# QN908XC register map
Vendor: nxp.com; File version: 1.0
CPU: CM4 r0p1, little endian, no MPU, no FPU, 0x3 interrupt priority bits, 0x0 interrupts
Registers are 32-bit, read-write, reset 0x0 unless marked. A register's access mark holds for its fields unless they carry their own. Offsets are from the block's base; [hi:lo] are bit positions; {n}, {i} and the like mark numbered series.

## SYSCON
Base 0x40000000
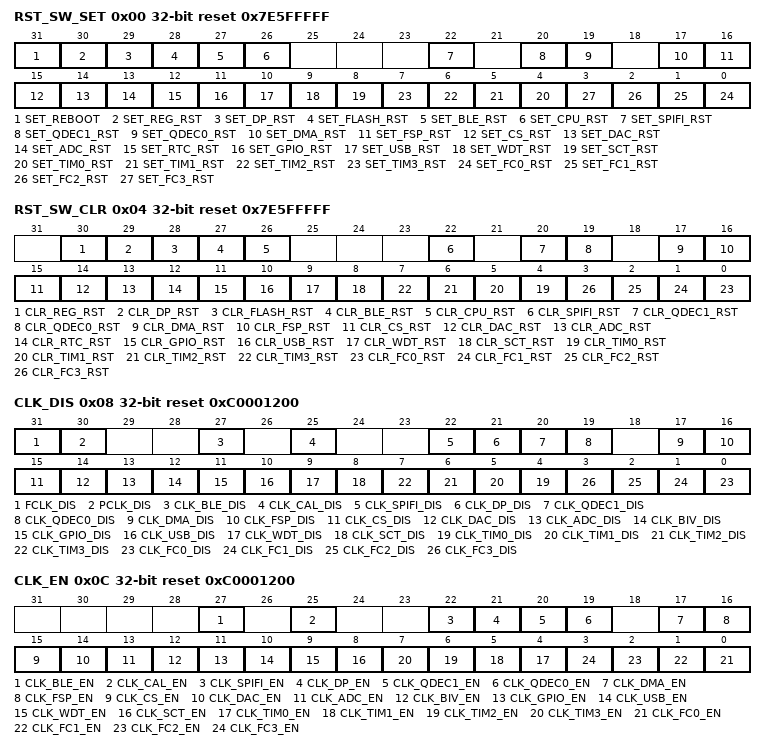
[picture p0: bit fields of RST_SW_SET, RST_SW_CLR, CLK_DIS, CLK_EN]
0x00 RST_SW_SET reset 0x7E5FFFFF — block software reset set register
  [31] SET_REBOOT wo — Write 1 to Reboot entire system
  [30] SET_REG_RST wo — Write 1 to reset retention register
  [29] SET_DP_RST wo — Write 1 to set DataPath reset
  [28] SET_FLASH_RST wo — Write 1 to set flash controller reset
  [27] SET_BLE_RST wo — Write 1 to set BLE reset
  [26] SET_CPU_RST wo — Write 1 to set CPU reset
  [22] SET_SPIFI_RST wo — Write 1 to set SPIFI reset
  [20] SET_QDEC1_RST wo — Write 1 to set QDEC 1 reset
  [19] SET_QDEC0_RST wo — Write 1 to set QDEC 0 reset
  [17] SET_DMA_RST wo — Write 1 to set DMA reset
  [16] SET_FSP_RST wo — Write 1 to set FSP reset
  [15] SET_CS_RST wo — Write 1 to set Cap sensor interface reset
  [14] SET_DAC_RST wo — Write 1 to set DAC interface reset
  [13] SET_ADC_RST wo — Write 1 to set ADC interface reset
  [12] SET_RTC_RST wo — Write 1 to set RTC reset
  [11] SET_GPIO_RST wo — Write 1 to set GPIO reset
  [10] SET_USB_RST wo — Write 1 to set USB reset
  [9] SET_WDT_RST wo — Write 1 to set Watch Dog reset
  [8] SET_SCT_RST wo — Write 1 to set SCT reset
  [n+4] SET_TIM{n}_RST wo (n=0..3) — Write 1 to set CTIMER{n} reset
  [n] SET_FC{n}_RST wo (n=0..3) — Write 1 to set FLEXCOMM{n} reset
0x04 RST_SW_CLR reset 0x7E5FFFFF — block software reset clear register
  [30] CLR_REG_RST write-1-clears — Write 1 to clear retention register reset
  [29] CLR_DP_RST write-1-clears — Write 1 to clear DataPath reset
  [28] CLR_FLASH_RST write-1-clears — Write 1 to clear flash controller reset
  [27] CLR_BLE_RST write-1-clears — Write 1 to clear BLE reset
  [26] CLR_CPU_RST write-1-clears — Write 1 to clear CPU reset
  [22] CLR_SPIFI_RST write-1-clears — Write 1 to clear SPIFI reset
  [20] CLR_QDEC1_RST write-1-clears — Write 1 to clear QDEC 1 reset
  [19] CLR_QDEC0_RST write-1-clears — Write 1 to clear QDEC 0 reset
  [17] CLR_DMA_RST write-1-clears — Write 1 to clear DMA reset
  [16] CLR_FSP_RST write-1-clears — Write 1 to clear FSP reset
  [15] CLR_CS_RST write-1-clears — Write 1 to clear cap sensor interface reset
  [14] CLR_DAC_RST write-1-clears — Write 1 to clear DAC interface reset
  [13] CLR_ADC_RST write-1-clears — Write 1 to clear ADC interface reset
  [12] CLR_RTC_RST write-1-clears — Write 1 to clear RTC reset
  [11] CLR_GPIO_RST write-1-clears — Write 1 to clear GPIO reset
  [10] CLR_USB_RST write-1-clears — Write 1 to clear USB reset
  [9] CLR_WDT_RST write-1-clears — Write 1 to clear Watch Dog reset
  [8] CLR_SCT_RST write-1-clears — Write 1 to clear SCT reset
  [n+4] CLR_TIM{n}_RST write-1-clears (n=0..3) — Write 1 to clear CTIMER{n} reset
  [n] CLR_FC{n}_RST write-1-clears (n=0..3) — Write 1 to clear FLEXCOMM{n} reset
0x08 CLK_DIS reset 0xC0001200 — clock disable register
  [31] FCLK_DIS write-1-clears — Write 1 to disable CPU FCLK;
  [30] PCLK_DIS write-1-clears — Write 1 to disable PCLK of some logic;
  [27] CLK_BLE_DIS write-1-clears — Write 1 to disable BLE clock
  [25] CLK_CAL_DIS write-1-clears — Write 1 to disable Calibration clock;
  [22] CLK_SPIFI_DIS write-1-clears — Write 1 to disable SPIFI clock;
  [21] CLK_DP_DIS write-1-clears — Write 1 to disable Data Path 16/8MHz clock;
  [20] CLK_QDEC1_DIS write-1-clears — Write 1 to disable QDEC1 clock;
  [19] CLK_QDEC0_DIS write-1-clears — Write 1 to disable QDEC0 clock;
  [17] CLK_DMA_DIS write-1-clears — Write 1 to disable DMA clock
  [16] CLK_FSP_DIS write-1-clears — Write 1 to disable FSP clock;
  [15] CLK_CS_DIS write-1-clears — Write 1 to disable Cap sensor clock;
  [14] CLK_DAC_DIS write-1-clears — Write 1 to disable DAC clock;
  [13] CLK_ADC_DIS write-1-clears — Write 1 to disable ADC clock;
  [12] CLK_BIV_DIS write-1-clears — Write 1 to disable BIV APB clock include RTC BiV register.
  [11] CLK_GPIO_DIS write-1-clears — Write 1 to disable GPIO clock
  [10] CLK_USB_DIS write-1-clears — Write 1 to disable USB clock;
  [9] CLK_WDT_DIS write-1-clears — Write 1 to disable Watch Dog clock
  [8] CLK_SCT_DIS write-1-clears — Write 1 to disable SCT clock
  [n+4] CLK_TIM{n}_DIS write-1-clears (n=0..3) — Write 1 to disable CTIMER{n} clock
  [n] CLK_FC{n}_DIS write-1-clears (n=0..3) — Write 1 to disable FLEXCOMM{n} clock
0x0C CLK_EN reset 0xC0001200 — clock enable register
  [27] CLK_BLE_EN wo — Write 1 to enable BLE clock
  [25] CLK_CAL_EN wo — Write 1 to enable Calibration clock;
  [22] CLK_SPIFI_EN wo — Write 1 to enable SPIFI clock;
  [21] CLK_DP_EN wo — Write 1 to enable Data Path 16/8MHz clock;
  [20] CLK_QDEC1_EN wo — Write 1 to enable QDEC1 clock;
  [19] CLK_QDEC0_EN wo — Write 1 to enable QDEC0 clock;
  [17] CLK_DMA_EN wo — Write 1 to enable DMA clock
  [16] CLK_FSP_EN wo — Write 1 to enable FSP clock;
  [15] CLK_CS_EN wo — Write 1 to enable Cap sensor clock;
  [14] CLK_DAC_EN wo — Write 1 to enable DAC clock;
  [13] CLK_ADC_EN wo — Write 1 to enable ADC clock;
  [12] CLK_BIV_EN wo — Write 1 to enable BIV APB clock include RTC BiV register.
  [11] CLK_GPIO_EN wo — Write 1 to enable GPIO clock
  [10] CLK_USB_EN wo — Write 1 to enable USB clock;
  [9] CLK_WDT_EN wo — Write 1 to enable Watch Dog clock
  [8] CLK_SCT_EN wo — Write 1 to enable SCT clock
  [n+4] CLK_TIM{n}_EN wo (n=0..3) — Write 1 to enable CTIMER{n} clock
  [n] CLK_FC{n}_EN wo (n=0..3) — Write 1 to enable FLEXCOMM{n} clock
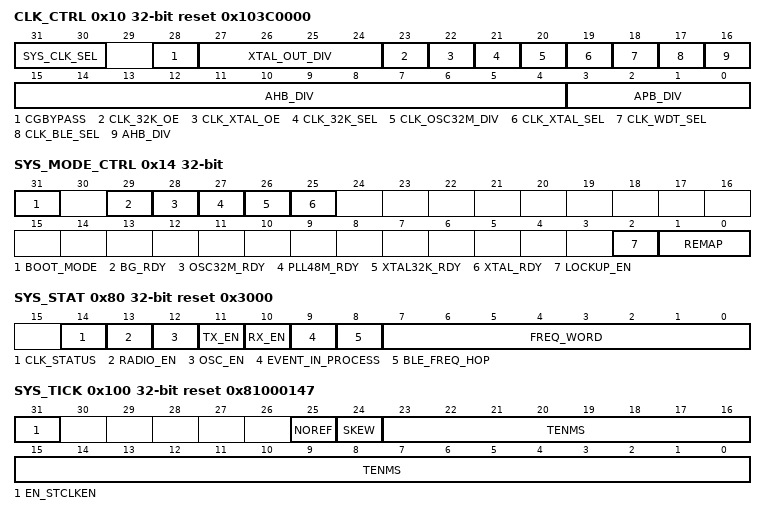
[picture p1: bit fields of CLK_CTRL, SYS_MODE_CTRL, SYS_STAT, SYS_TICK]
0x10 CLK_CTRL reset 0x103C0000 — system clock source and divider register
  [31:30] SYS_CLK_SEL — Select SYS_CLK source
    0=CLK_OSC (32M internal clock); 1=CLK_XTAL (external crystal clock); 2=CLK_32K (32K clock)
  [28] CGBYPASS — If it is 0, it can save CPU power in active mode
  [27:24] XTAL_OUT_DIV — high frequency xtal clock output divider
  [23] CLK_32K_OE — 32K clock output enable
  [22] CLK_XTAL_OE — system clock output enable
  [21] CLK_32K_SEL — 32K clock source selection
    0=XTAL32K (digital 32K clock source is external 32K crystal); 1=RCO32K (digital 32K clock source is internal 32K RCO)
  [20] CLK_OSC32M_DIV — digital OSC clock input selection
    0=BY1 (use original 32M RCO clock); 1=BY2 (divide 32M OSC clock into 16M)
  [19] CLK_XTAL_SEL — Crytal clock selection
    0=XTAL16M (external crystal is 16M); 1=XTAL32M (external crystal is 32M)
  [18] CLK_WDT_SEL — Select Watch Dog clock
    0=CLK_WDT_SEL_32K (watch dog run at 32K); 1=APB (watch dog run at APB clock)
  [17] CLK_BLE_SEL — BLE frequency indicator
    0=CLK_BLE_SEL_8M (BLE run at 8M); 1=CLK_BLE_SEL_16M (BLE run at 16M)
  [16:4] AHB_DIV — AHB_CLK = SYS_CLK / (AHB_DIV+1);Note Before enable BLE clock (CLK_BLE_EN =1) It is mandatory to set AHB_CLK = 32 or 16 or 8 MHz.
  [3:0] APB_DIV — APB_CLK = AHB_CLK/(APB_DIV+1)
0x14 SYS_MODE_CTRL — system mode and address remap register
  [31] BOOT_MODE ro — boot mode pin status
    0=ISP (when BOOT_MODE pin is 0, bootloader enter ISP); 1=NORMAL (when BOOT_MODE pin is 1, bootloader jump to flash without ISP)
  [29] BG_RDY ro — BG ready readout
  [28] OSC32M_RDY ro — 32MHz oscillator ready readout
  [27] PLL48M_RDY ro — 48MHz PLL ready readout
  [26] XTAL32K_RDY ro — 32KHz xtal ready readout
  [25] XTAL_RDY ro — 16/32 MHz xtal ready readout
  [2] LOCKUP_EN — lock up enable
  [1:0] REMAP — software remap system address
    0=ROM (address 0 is mapped to ROM); 1=FLASH (address 0 is mapped to FLASH); 2=RAM (address 0 is mapped to RAM)
0x80 SYS_STAT ro reset 0x3000 — system status register
  [14] CLK_STATUS — BLE status
    0=BLE_IP_ACT (BLE is active); 1=BLE_IP_SLP (BLE is in sleep mode)
  [13] RADIO_EN — BLE radio_en output;
  [12] OSC_EN — BLE osc_en output;
  [11] TX_EN — when 1, system is in TX state
  [10] RX_EN — when 1, system is in RX state
  [9] EVENT_IN_PROCESS — BLE event indicator
    0=BLE_NONE_ENV (BLE is not in event process); 1=BLE_IN_ENV (BLE is in event process)
  [8] BLE_FREQ_HOP — BLE frequency word change flag;
  [7:0] FREQ_WORD — BLE Frequency word;
0x100 SYS_TICK reset 0x81000147 — systick timer control register
  [31] EN_STCLKEN — 1 is enable STCLKEN;
  [25] NOREF — whether an external reference clock is available
    0=AVAILABLE (external reference clock is available); 1=NOT_AVAILABLE (external reference clock is not available)
  [24] SKEW — whether THE TENMS value will generate a precise 10 millisencod time or an approximation
    0=PRECISE (TENMS is considered to be precise); 1=NOT_PRECISE (TENMS is not considered to be precise)
  [23:0] TENMS — system tick timer calibration value
0x104 SRAM_CTRL reset 0x2400 — Exchange memory base address register
  [14:0] EM_BASE_ADDR — Exchange memory base address in system memory. Default value is 9K word.
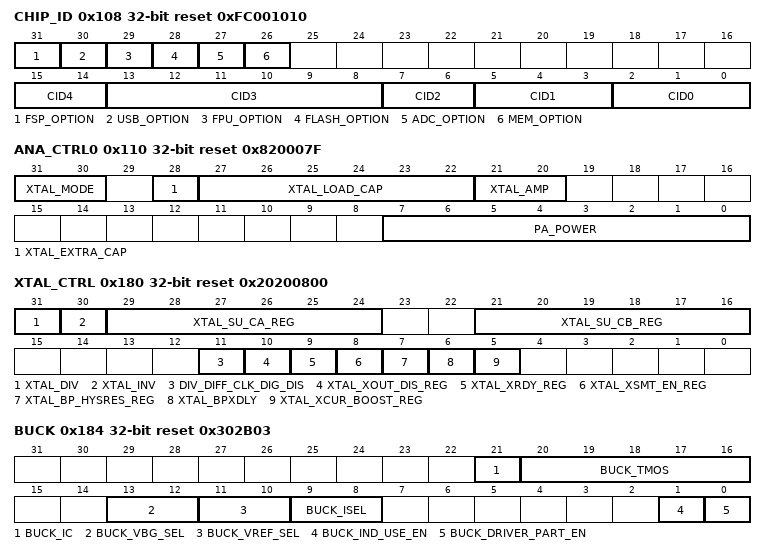
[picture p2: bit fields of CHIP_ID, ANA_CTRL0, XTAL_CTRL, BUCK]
0x108 CHIP_ID ro reset 0xFC001010
  [31] FSP_OPTION — fsp bond indicator
    0=NONE (chip doesnot have FSP); 1=EXIST (chip has FSP)
  [30] USB_OPTION — usb bond indicator
    0=NONE (chip doesnot have USB); 1=EXIST (chip has USB)
  [29] FPU_OPTION — fpu bond indicator
    0=NONE (fpu is not exist); 1=EXIST (fpu is exist)
  [28] FLASH_OPTION — flash bond indicator
    0=FLASH_OPTION_256K (chip flash size is 256K); 1=FLASH_OPTION_512K (chip flash size is 512K)
  [27] ADC_OPTION — adc bond indicator
    0=LOW (adc low resolution); 1=HIGH (adc high resolution)
  [26] MEM_OPTION — memory bond indicator
    0=MEM_OPTION_64K (chip memory size is 64K); 1=MEM_OPTION_128K (chip memory size is 128K)
  [15:14] CID4 — CHIP ID for major revision
    0=A (revision A); 1=B (revision B); 2=C (revision C); 3=D (revision D)
  [13:8] CID3 — CHIP ID for product ID
    0=QN9020; 1=QN9030; 2=QN9080
  [7:6] CID2 — CHIP ID for minor revision
  [5:3] CID1 — CHIP ID for product family
  [2:0] CID0 — CHIP ID for manufacture fab
0x110 ANA_CTRL0 reset 0x820007F — crystal and PA register
  [31:30] XTAL_MODE — Injection mode of the XTAL
    0=XTAL (High frequency crystal oscillator); 1=DIG (Inject digital clock); 2=SINGLE (Inject single-end sine-wave signal); 3=DIFF (inject differential sine-wave signal)
  [28] XTAL_EXTRA_CAP — Add extra 16/32 MHz xtal load cap
  [27:22] XTAL_LOAD_CAP — Register controlled load cap of the XTAL in normal modeLOAD_CAP=5pF+0.35pF*CSEL+5pF*XADD_C
  [21:20] XTAL_AMP — crystal amplitude set register
  [7:0] PA_POWER — PA power control (all of below is minus data)
    16=PA_POWER_20DBM (20dBm); 18=PA_POWER_18DBM (18dBm); 20=PA_POWER_16DBM (16dBm); 25=PA_POWER_14DBM (14dBm); 32=PA_POWER_12DBM (12dBm); 40=PA_POWER_10DBM (10dBm); 50=PA_POWER_8DBM (8dBm); 64=PA_POWER_6DBM (6dBm); 80=PA_POWER_4DBM (4dBm); 101=PA_POWER_2DBM (2dBm); 127=PA_POWER_0DBM (0dBm)
0x180 XTAL_CTRL reset 0x20200800 — crystal control register
  [31] XTAL_DIV — Divide crystal clock when external crystal is 32M this bit should be configured into 1 otherwise 0.
  [30] XTAL_INV — Inverse crystal clock
  [29:24] XTAL_SU_CA_REG — Register controlled load cap of the XTAL_A in speed up modeCA=2pF+0.35pF*SU_CA+5pF*XADD_C
  [21:16] XTAL_SU_CB_REG — Register controlled load cap of the XTAL_B in speed up modeCB=2pF+0.35pF*SU_CB+5pF*XADD_C
  [11] DIV_DIFF_CLK_DIG_DIS — disable differential clock of digital
  [10] XTAL_XOUT_DIS_REG — 1 not to send 16/32 MHz xtal clk out
  [9] XTAL_XRDY_REG — 1 to set xtal ready signal by register
  [8] XTAL_XSMT_EN_REG — 1 to use hysteresis buffer
  [7] XTAL_BP_HYSRES_REG — 1 to bypass the degeneration resistor in order to reduce the hysteresis voltage
  [6] XTAL_BPXDLY — Bypass the power up delay in the XTAL core.
  [5] XTAL_XCUR_BOOST_REG — 1 to increase 16/32 MHz xtal current
0x184 BUCK reset 0x302B03 — buck control register
  [21] BUCK_IC — frequency compensation versus BVDD variation
  [20:16] BUCK_TMOS — buck constant on time control
  [13:12] BUCK_VBG_SEL — buck reference setting
  [11:10] BUCK_VREF_SEL — buck current setting
  [9:8] BUCK_ISEL — buck current bias control
  [1] BUCK_IND_USE_EN — 1 to turn on buck output stage gradually
  [0] BUCK_DRIVER_PART_EN — 1 to short external inductor
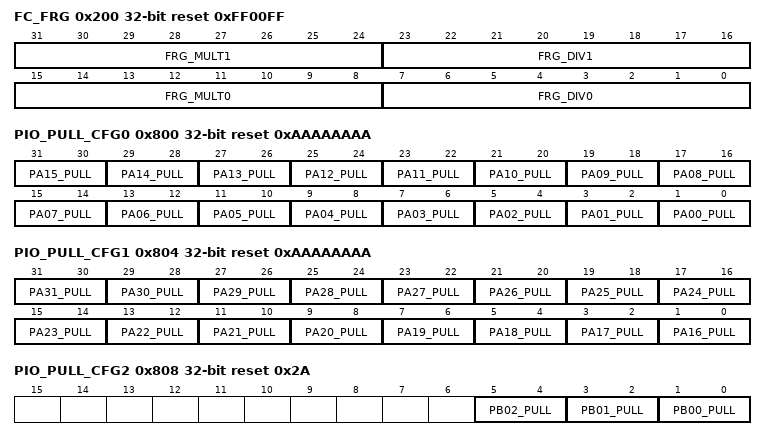
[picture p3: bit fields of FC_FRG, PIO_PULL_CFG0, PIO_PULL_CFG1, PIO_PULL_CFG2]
0x200 FC_FRG reset 0xFF00FF — flexcomm 0 and 1 clock divider register
  [31:24] FRG_MULT1 — flexcomm1 clock generator, Numerator of the fractional divider. MULT is equal to the programmed value
  [23:16] FRG_DIV1 — flexcomm1 clock generator, Denominator of the fractional divider. DIV is equal to the programmed value +1. Always set to 0xFF to use with the fractional baud rate generator.
  [15:8] FRG_MULT0 — flexcomm0 clock generator, Numerator of the fractional divider. MULT is equal to the programmed value
  [7:0] FRG_DIV0 — flexcomm0 clock generator, Denominator of the fractional divider. DIV is equal to the programmed value +1. Always set to 0xFF to use with the fractional baud rate generator.
0x800 PIO_PULL_CFG0 reset 0xAAAAAAAA — pad pull control register 0
  [2n+1:2n] PA{n:02}_PULL (n=0..15) — PA{n:02} pull control register
0x804 PIO_PULL_CFG1 reset 0xAAAAAAAA — pad pull control register 1
  [2n-31:2n-32] PA{n}_PULL (n=16..31) — PA{n} pull control register
0x808 PIO_PULL_CFG2 reset 0x2A — pad pull control register 2
  [5:4] PB02_PULL — PB02 pull control register
  [3:2] PB01_PULL — PB01 pull control register
  [1:0] PB00_PULL — PB00 pull control register
0x80C IO_CAP reset not defined — io status capture register
  [0] PIN_RETENTION wo — Write 1 to capture pad output and output enable and the status will be saved in PIN_SLP_OEN0 PIN_SLP_OEN1 PIN_SLP_OUT0 and PIN_SLP_OUT1.
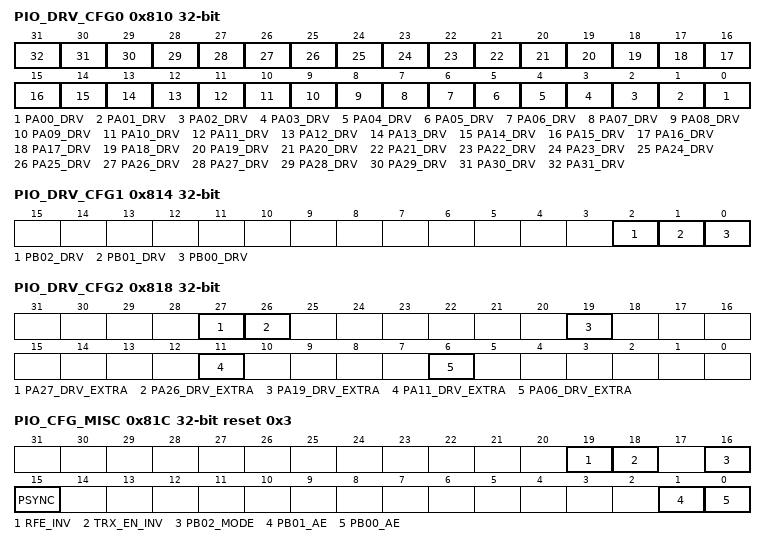
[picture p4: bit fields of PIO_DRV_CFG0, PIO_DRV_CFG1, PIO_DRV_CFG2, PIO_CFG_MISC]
0x810 PIO_DRV_CFG0 — pad drive strength register 0
  [n] PA{n:02}_DRV (n=0..31) — PA{n:02} drive strength register
0x814 PIO_DRV_CFG1 — pad drive strength register 1
  [2] PB02_DRV — PB02 drive strengh register
  [1] PB01_DRV — PB01 drive strengh register
  [0] PB00_DRV — PB00 drive strengh register
0x818 PIO_DRV_CFG2 — pad drive extra register
  [27] PA27_DRV_EXTRA — Write 1 to enable extra driven on PA27
  [26] PA26_DRV_EXTRA — Write 1 to enable extra driven on PA26
  [19] PA19_DRV_EXTRA — Write 1 to enable extra driven on PA19
  [11] PA11_DRV_EXTRA — Write 1 to enable extra driven on PA11
  [6] PA06_DRV_EXTRA — Write 1 to enable extra driven on PA06
0x81C PIO_CFG_MISC reset 0x3 — pin misc control register
  [19] RFE_INV — Inverse RFE polarity
    0=RFE_POL (Inverse RFE polarity)
  [18] TRX_EN_INV — inverse TX_EN & RX_EN pin mux output polarity
    0=TRX_EN_POL (inverse TX_EN & RX_EN pin mux output polarity)
  [16] PB02_MODE — chip mode pin function select
    0=BOOT_MODE (PB02 is used as chip mode input); 1=ANTENNA (PB02 is used as antena output)
  [15] PSYNC — when 1, bypass first stage of synchronization of DMA pin trigger
  [1] PB01_AE — Enable PB01 analog function
  [0] PB00_AE — Enable PB00 analog function
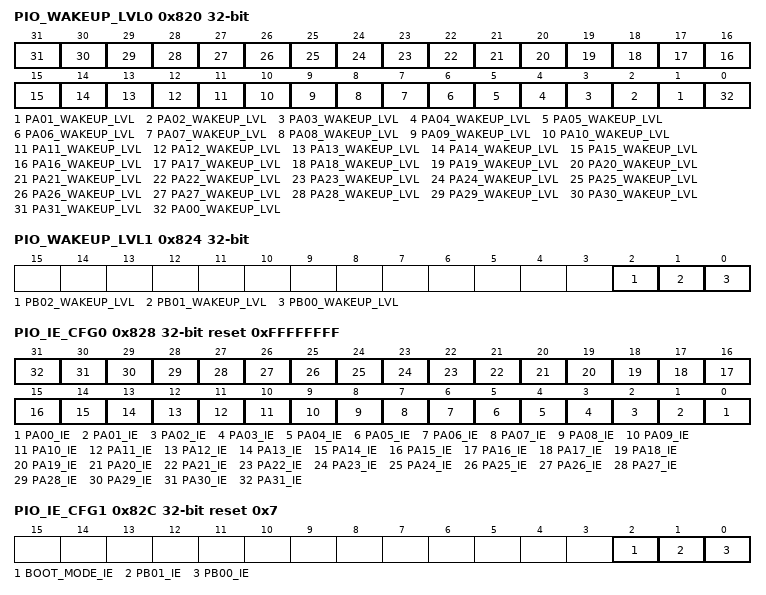
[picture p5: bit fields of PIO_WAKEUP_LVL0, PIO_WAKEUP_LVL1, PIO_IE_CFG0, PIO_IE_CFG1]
0x820 PIO_WAKEUP_LVL0 — pin wakeup polarity register 0
  [n] PA{n:02}_WAKEUP_LVL (n=1..31) — Control the wake up polarity of PA{n:02} in sleep mode.
  [0] PA00_WAKEUP_LVL — Control the wake up polarity of PA00 in sleep mode. 0: high level wakeup, 1: low level wakeup
0x824 PIO_WAKEUP_LVL1 — pin wakeup polarity register 1
  [2] PB02_WAKEUP_LVL — Control the wake up polarity of PB03 in sleep mode.
  [1] PB01_WAKEUP_LVL — Control the wake up polarity of PB02 in sleep mode.
  [0] PB00_WAKEUP_LVL — Control the wake up polarity of PB01 in sleep mode.
0x828 PIO_IE_CFG0 reset 0xFFFFFFFF — pad input enable register 0
  [n] PA{n:02}_IE (n=0..31) — PA{n:02} digital input enable
0x82C PIO_IE_CFG1 reset 0x7 — pad input enable register 1
  [2] BOOT_MODE_IE — PB02 input enable
  [1] PB01_IE — PB01 digital input enable
  [0] PB00_IE — PB00 digital input enable
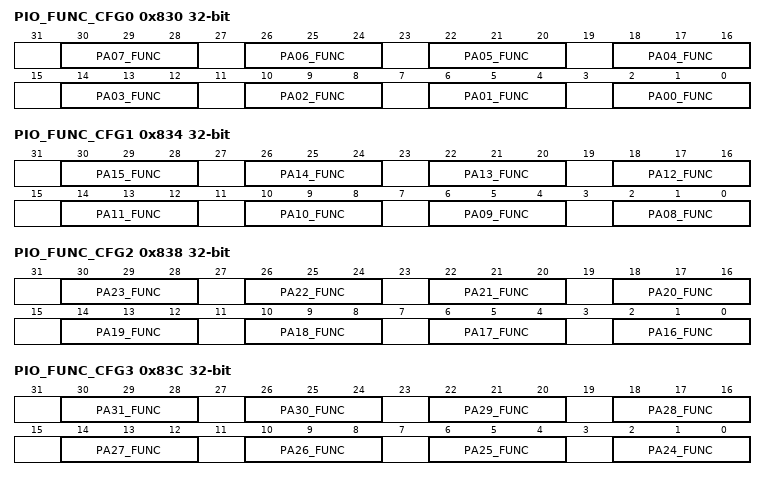
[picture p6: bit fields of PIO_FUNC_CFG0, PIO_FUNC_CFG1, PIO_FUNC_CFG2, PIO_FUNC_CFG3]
0x830 PIO_FUNC_CFG0 — pin mux control register 0
  [4n+2:4n] PA{n:02}_FUNC (n=0..7) — PA{n:02} function control register
0x834 PIO_FUNC_CFG1 — pin mux control register 1
  [4n-30:4n-32] PA{n:02}_FUNC (n=8..15) — PA{n:02} function control register
0x838 PIO_FUNC_CFG2 — pin mux control register 2
  [4n-62:4n-64] PA{n}_FUNC (n=16..23) — PA{n} function control register
0x83C PIO_FUNC_CFG3 — pin mux control register 3
  [4n-94:4n-96] PA{n}_FUNC (n=24..31) — PA{n} function control register
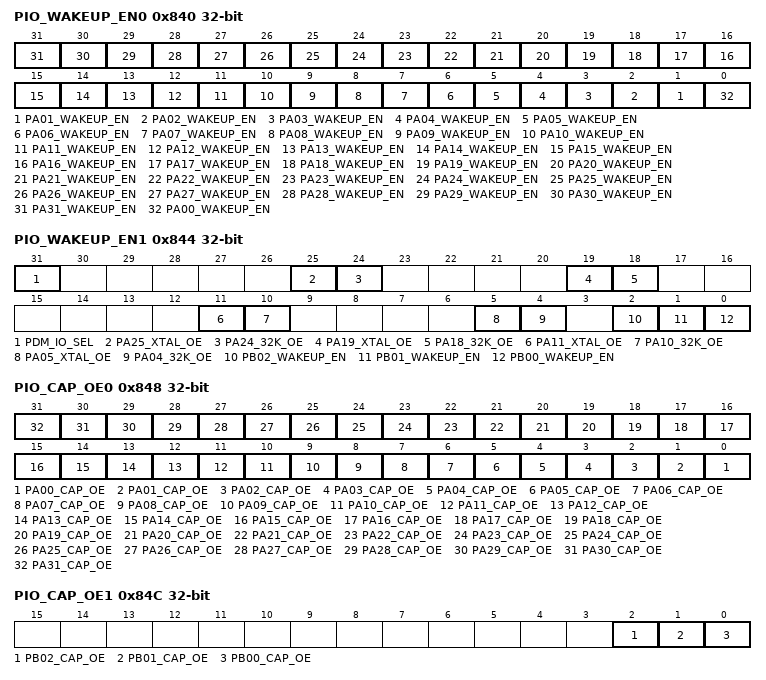
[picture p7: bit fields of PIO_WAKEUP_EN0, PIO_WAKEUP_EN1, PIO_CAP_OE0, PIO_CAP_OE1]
0x840 PIO_WAKEUP_EN0 — pin function selection in power down mode register 0
  [n] PA{n:02}_WAKEUP_EN (n=1..31)
  [0] PA00_WAKEUP_EN — Control GPIOA[31-0] as Wakeup source.
0x844 PIO_WAKEUP_EN1 — pin function selection in power down mode register 1
  [31] PDM_IO_SEL — pin status selection in power down mode
  [25] PA25_XTAL_OE — XTAL clock output enable. When this bit is set to 1 PA25 will output XTAL clock. At this time PIN_CTRL register is not effective to control this IO's function.
  [24] PA24_32K_OE — 32K clock output enable. When this bit is set to 1 PA24 will output 32k clock. At this time PIN_CTRL register is not effective to control this IO's function.
  [19] PA19_XTAL_OE — XTAL clock output enable. When this bit is set to 1 PA19 will output XTAL clock. At this time PIN_CTRL register is not effective to control this IO's function.
  [18] PA18_32K_OE — 32K clock output enable. When this bit is set to 1 PA18 will output 32k clock. At this time PIN_CTRL register is not effective to control this IO's function.
  [11] PA11_XTAL_OE — XTAL clock output enable. When this bit is set to 1 PA11 will output XTAL clock. At this time PIN_CTRL register is not effective to control this IO's function.
  [10] PA10_32K_OE — 32K clock output enable. When this bit is set to 1 PA10 (GPIO10) will output 32k clock. At this time PIN_CTRL register is not effective to control this IO's function.
  [5] PA05_XTAL_OE — XTAL clock output enable. When this bit is set to 1 PA05 will output XTAL clock. At this time PIN_CTRL register is not effective to control this IO's function.
  [4] PA04_32K_OE — 32K clock output enable. When this bit is set to 1 PA04 will output 32k clock. At this time PIN_CTRL register is not effective to control this IO's function.
  [2] PB02_WAKEUP_EN
  [1] PB01_WAKEUP_EN
  [0] PB00_WAKEUP_EN — Control GPIOB as Wakeup source.
0x848 PIO_CAP_OE0 ro — pin output enable status register 0 while captured by writing 1 to IO_CAP
  [n] PA{n:02}_CAP_OE (n=0..31) — PA{n:02} output enable status captured by writing 1 to IO_CAP
0x84C PIO_CAP_OE1 ro — pin output enable status register 1 while captured by writing 1 to IO_CAP
  [2] PB02_CAP_OE — PB02 output enable status captured by writing 1 to IO_CAP
  [1] PB01_CAP_OE — PB01 output enable status captured by writing 1 to IO_CAP
  [0] PB00_CAP_OE — PB00 output enable status captured by writing 1 to IO_CAP
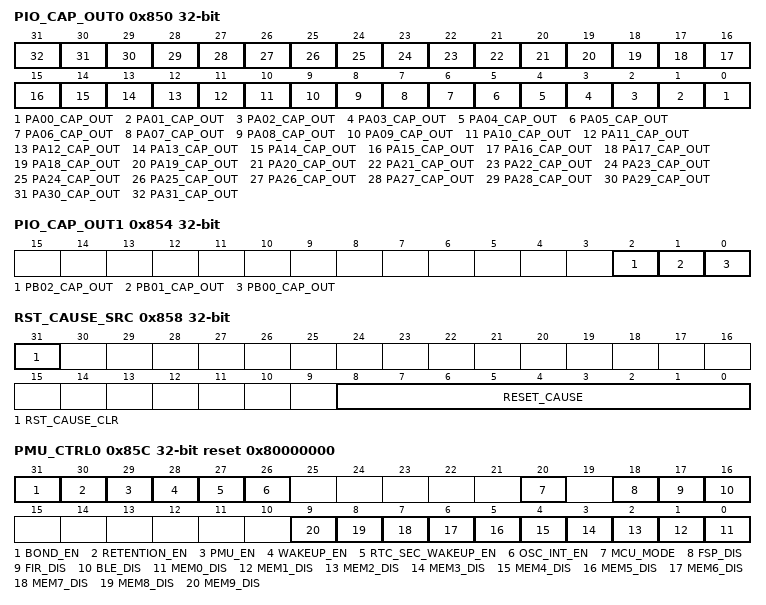
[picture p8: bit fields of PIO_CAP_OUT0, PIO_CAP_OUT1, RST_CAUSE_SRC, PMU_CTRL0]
0x850 PIO_CAP_OUT0 ro — pin output status register 0 while captured by writing 1 to IO_CAP
  [n] PA{n:02}_CAP_OUT (n=0..31) — PA{n:02} output status captured by writing 1 to IO_CAP
0x854 PIO_CAP_OUT1 ro — pin output status register 0 while captured by writing 1 to IO_CAP
  [2] PB02_CAP_OUT — PB02 output status while captured by writing 1 to IO_CAP
  [1] PB01_CAP_OUT — PB01 output status while captured by writing 1 to IO_CAP
  [0] PB00_CAP_OUT — PB00 output status while captured by writing 1 to IO_CAP
0x858 RST_CAUSE_SRC (reset mask 0x1FF) — reset source status register
  [31] RST_CAUSE_CLR wo — Write '1' clear RESET_CAUSE bits;
  [8:0] RESET_CAUSE ro — reset source indicator. xxxxxxxx1b = Power-on Reset; xxxxxxx1xb = Brown-Down Reset; xxxxxx1xxb = External pin Reset; xxxxx1xxxb = Watch Dog Reset; xxxx1xxxxb = Lock Up Reset; xxx1xxxxxb = Reboot Reset; xx1000000b = CPU system Reset requirement; x10000000b = Wake Up reset 10000000b = CPU software Reset;
0x85C PMU_CTRL0 reset 0x80000000 — power management uinit control register 0
  [31] BOND_EN — 1 to enable FSP_BOND_EN bond option
  [30] RETENTION_EN — 1 to enable all CPU registers to be retentioned in sleep mode
  [29] PMU_EN — 1 to enable chip power down mode
  [28] WAKEUP_EN — 1 to enable sleep wake up source
  [27] RTC_SEC_WAKEUP_EN — 1 to enable RTC interrupt as wakeup source
  [26] OSC_INT_EN — 1 to enable OSC_EN as interrupt and wakeup source
  [20] MCU_MODE — power control of BG, V2I, VREG_A, VREG_D
    0=ANA_PWRON (power on BG, V2I, VREG_A, VREG_D); 1=ANA_PWROFF (power off BG, V2I, VREG_A, VREG_D)
  [18] FSP_DIS — power down FSP
  [17] FIR_DIS — power down FIR buffer
  [16] BLE_DIS — power down BLE
  [n] MEM{n}_DIS (n=0..9) — power down sram memory block {n}
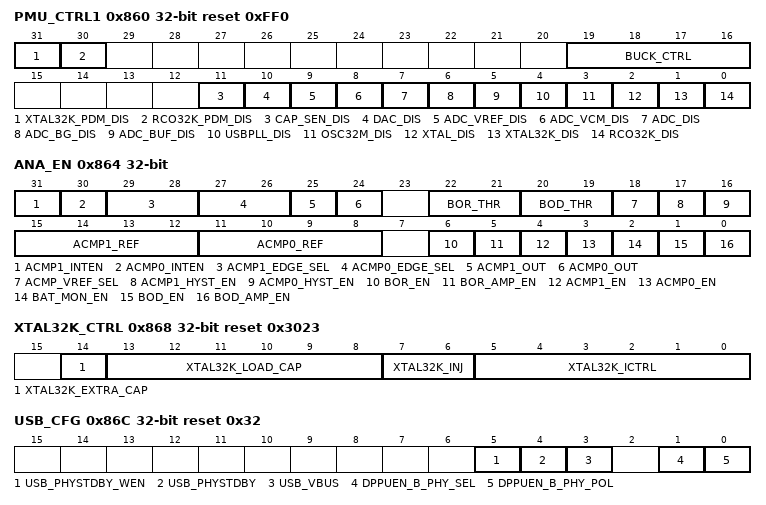
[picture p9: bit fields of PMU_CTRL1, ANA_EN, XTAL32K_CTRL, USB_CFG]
0x860 PMU_CTRL1 reset 0xFF0 — power management uinit control register 1
  [31] XTAL32K_PDM_DIS — In sleep mode this bit ORs with DIS_XTAL32K to control the XTAL32 power
  [30] RCO32K_PDM_DIS — In sleep mode this bit ORs with DIS_RCO_32K to control the RCO 32K power
  [19:16] BUCK_CTRL — BUCK power control, 0x00 to power on, and 0x0F to power down
  [11] CAP_SEN_DIS — 1 to switch off CAP_SEN
  [10] DAC_DIS — 1 to switch off DAC
  [9] ADC_VREF_DIS — 1 to switch off VREF DRV in SD ADC
  [8] ADC_VCM_DIS — 1 to switch off VCM DRV in SD ADC
  [7] ADC_DIS — 1 to switch off SD ADC
  [6] ADC_BG_DIS — 1 to switch off bandgap in SD ADC
  [5] ADC_BUF_DIS — 1 to switch off buffer in SD ADC
  [4] USBPLL_DIS — 1 to switch off USB 48M PLL power
  [3] OSC32M_DIS — 1 to switch off 32M OSC power
  [2] XTAL_DIS — 1 to switch off XTAL of digital power
  [1] XTAL32K_DIS — 1 to switch off 32K XTAL power
  [0] RCO32K_DIS — 1 to switch off 32K RCO power
0x864 ANA_EN — analog setting register
  [31] ACMP1_INTEN — 1 to enable ACMP1 interrupt
  [30] ACMP0_INTEN — 1 to enable ACMP0 interrupt
  [29:28] ACMP1_EDGE_SEL — ACMP1 interrupt edge selection
  [27:26] ACMP0_EDGE_SEL — ACMP0 interrupt edge selection
    0=POSEDGE; 1=NEGEDGE; 2=BOTHEDGE
  [25] ACMP1_OUT ro — Comparator 1 output.
  [24] ACMP0_OUT ro — Comparator 0 output.
  [22:21] BOR_THR — Browned-out reset threshold voltages
    0=trigger at 1.5V; 1=trigger at 1.85V; 2=trigger at 2V; 3=trigger at 2.3V
  [20:19] BOD_THR — Browned-out detector threshold voltages, when VDD is lower than this voltage, BOD_OUT interrupt happens. And the detector has a hysteresis.
    0=trigger at 2.06V, with 295mV hysteresis; 1=trigger at 2.45V, with 350mV hysteresis; 2=trigger at 2.72V, with 388mV hysteresis; 3=trigger at 3.04V, with 435mV hysteresis
  [18] ACMP_VREF_SEL — Acmp_vref selection
  [17] ACMP1_HYST_EN — Hysteresis enable of ACMP1 when 1
  [16] ACMP0_HYST_EN — Hysteresis enable of ACMP0 when 1
  [15:12] ACMP1_REF — acmp1 reference voltage selection, vref1=Acmp_vref*ACMP1_REF/16
  [11:8] ACMP0_REF — acmp0 reference voltage selection, vref0=Acmp_vref*ACMP0_REF/16
  [6] BOR_EN — Enable browned reset detector
  [5] BOR_AMP_EN — Enable the AMP of browned reset detector
  [4] ACMP1_EN — Enable comparator 1
  [3] ACMP0_EN — Enable comparator 0
  [2] BAT_MON_EN — Enable battery monitor
  [1] BOD_EN — Enable browned out detector
  [0] BOD_AMP_EN — Enable the AMP of browned out detector
0x868 XTAL32K_CTRL reset 0x3023 — crystal 32K control register
  [14] XTAL32K_EXTRA_CAP — add extra xtal32 load cap
  [13:8] XTAL32K_LOAD_CAP — load cap selection of xtal32
  [7:6] XTAL32K_INJ — Xtal 32KHz clk injection mode1xb = external sine wave clock
    0=ONCHIP_OSC (on-chip oscillator); 1=EXT_DIG_CLK (external digital clock)
  [5:0] XTAL32K_ICTRL — Xtal 32 gm cell current bias Y
0x86C USB_CFG reset 0x32 — USB configuration register
  [5] USB_PHYSTDBY_WEN — 1 to enable USB_PHYSTDBY control by register
  [4] USB_PHYSTDBY — 1 to enable USB_PHY in standby mode
    0=ON (USB PHY power is on); 1=OFF (USB PHY power is off)
  [3] USB_VBUS — USB connection voltage selection
  [1] DPPUEN_B_PHY_SEL — The control source selection for pull-up resistor
    0=BY_REG (connection controlled by register); 1=BY_USBCTRL (connection controlled by USB controller)
  [0] DPPUEN_B_PHY_POL — drive high to inverse the polarity of the connection
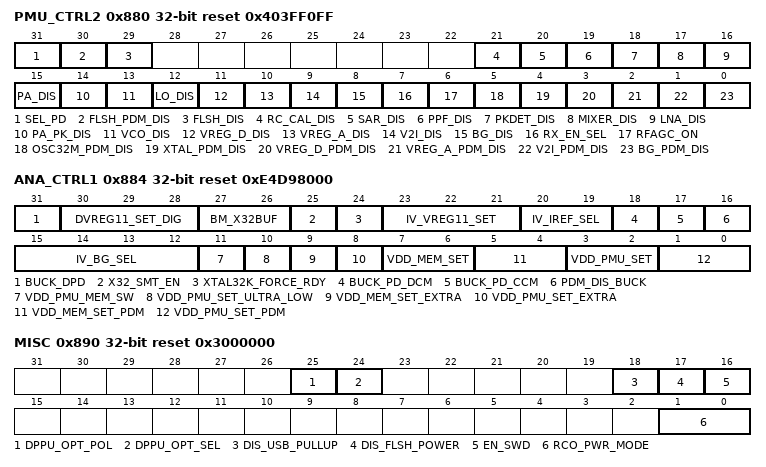
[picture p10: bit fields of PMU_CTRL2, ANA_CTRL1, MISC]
0x880 PMU_CTRL2 reset 0x403FF0FF — power management uinit control register 2
  [31] SEL_PD — power control selection
    0=HW_PWR (hardware control power); 1=SW_PWR (software control power)
  [30] FLSH_PDM_DIS — 1 to power down flash VDD25 in power down mode
  [29] FLSH_DIS — 1 to switch off flash power
  [21] RC_CAL_DIS — 1 to switch off RCCAL power
  [20] SAR_DIS — 1 to switch off SAR ADC power
  [19] PPF_DIS — 1 to switch off PPF power
  [18] PKDET_DIS — 1 to switch off RRF and PPF peek detector power
  [17] MIXER_DIS — 1 to switch off MIXER power
  [16] LNA_DIS — 1 to switch off LNA power
  [15] PA_DIS — 1 to switch off PA power
  [14] PA_PK_DIS — 1 to switch off PA peek detector power
  [13] VCO_DIS — 1 to switch off VCO power
  [12] LO_DIS — 1 to switch off LO power
  [11] VREG_D_DIS — 1 to switch off VREG_D power
  [10] VREG_A_DIS — 1 to switch off VREG_A power
  [9] V2I_DIS — 1 to switch off V2I power
  [8] BG_DIS — 1 to switch off bandcap power
  [7] RX_EN_SEL — RX_EN width selection
    0=EX_NOISE (exclude noise phase); 1=IN_NOISE (include noise phase)
  [6] RFAGC_ON — 1 to enable RFAGC
  [5] OSC32M_PDM_DIS — 1 to power down OSC32M in power down mode
  [4] XTAL_PDM_DIS — 1 to power down XTAL in power down mode
  [3] VREG_D_PDM_DIS — 1 to power down VREG_D in power down mode
  [2] VREG_A_PDM_DIS — 1 to power down VREG_A in power down mode
  [1] V2I_PDM_DIS — 1 to power down V2I in power down mode
  [0] BG_PDM_DIS — 1 to power down bandcap in power down mode
0x884 ANA_CTRL1 reset 0xE4D98000 — IVREF and DVREG setting register
  [31] BUCK_DPD — ZC control select
  [30:28] DVREG11_SET_DIG — Vregd set
  [27:26] BM_X32BUF — Xtal 32 buffer current bias
  [25] X32_SMT_EN — 1 to enable schmidt trigger in xtal32
  [24] XTAL32K_FORCE_RDY — Xtal32k ready from register
  [23:21] IV_VREG11_SET — VREG11 setting
  [20:19] IV_IREF_SEL — Reference current select
  [18] BUCK_PD_DCM — 0 buck in DCM mode
  [17] BUCK_PD_CCM — 0 buck in CCM mode
  [16] PDM_DIS_BUCK — 1 to power off buck in power down mode
  [15:12] IV_BG_SEL — VBG voltage select-
  [11] VDD_PMU_MEM_SW — 1 to close the switch betwwen vdd_omu and vdd_mem
  [10] VDD_PMU_SET_ULTRA_LOW — ultra low setting for vdd_pmu
  [9] VDD_MEM_SET_EXTRA — extra high setting for vdd_mem
  [8] VDD_PMU_SET_EXTRA — extra high setting for vdd_pmu
  [7:6] VDD_MEM_SET — Vdd_mem while wakeup
  [5:4] VDD_MEM_SET_PDM — Vdd_mem while in power down mode
  [3:2] VDD_PMU_SET — Vdd_pmu while wakeup
  [1:0] VDD_PMU_SET_PDM — Vdd_pmu while in power down
0x890 MISC reset 0x3000000 (reset mask 0x3000000)
  [25] DPPU_OPT_POL — swap pull up strength value
  [24] DPPU_OPT_SEL — pull up strength source. 0: from DPPU_OPT_POL, 1: from usb device
    0=RES1P2K (1.2kohm); 1=RES2P3K (2.3kohm)
  [18] DIS_USB_PULLUP — USB pull resister connection
    0=CONNECT (USB pull up resistor state depend on other 3 USB control register); 1=DISCONNECT (USB pull up resister is disconnected)
  [17] DIS_FLSH_POWER — flash power disable
    0=ENABLE (flash power is depend on the value DIS_FLSH of PMU_CTRL2); 1=DISABLE (flash power is off)
  [16] EN_SWD — enable swd register when SWD is selected in PIO_FUNC_CTRL
    0=DISABLE (disable SWD); 1=ENABLE (enable SWD)
  [1:0] RCO_PWR_MODE — RCO VDD selection
    0=RCO_PWR_HIGH (The highest RCO VDD setting, RCO current 630nA); 2=RCO_PWR_MIDDLE (The middle RCO VDD setting, RCO current 350nA); 3=RCO_PWR_LOW (The lowest RCO VDD setting, RCO current 200nA)
